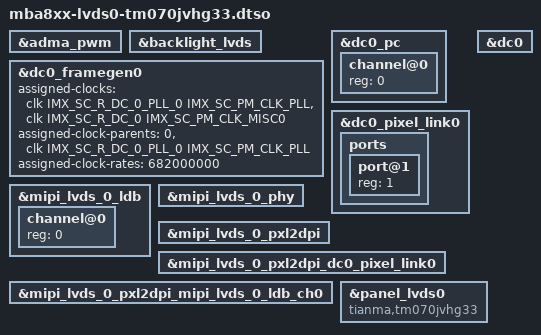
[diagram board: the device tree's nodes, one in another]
// SPDX-License-Identifier: (GPL-2.0-or-later OR MIT)
/*
 * Copyright (c) 2021-2026 TQ-Systems GmbH <linux@ew.tq-group.com>,
 * D-82229 Seefeld, Germany.
 * Author: Alexander Stein
 */

/dts-v1/;
/plugin/;

#include <dt-bindings/firmware/imx/rsrc.h>

&adma_pwm {
	status = "okay";
};

&backlight_lvds {
	status = "okay";
};

&dc0_framegen0 {
	assigned-clocks = <&clk IMX_SC_R_DC_0_PLL_0 IMX_SC_PM_CLK_PLL>,
			  <&clk IMX_SC_R_DC_0 IMX_SC_PM_CLK_MISC0>;
	assigned-clock-parents = <0>,
				 <&clk IMX_SC_R_DC_0_PLL_0 IMX_SC_PM_CLK_PLL>;
	assigned-clock-rates = <682000000>;
};

&dc0_pc {
	#address-cells = <1>;
	#size-cells = <0>;
	status = "okay";

	channel@0 {
		reg = <0>;
		status = "okay";
	};
};

&dc0_pixel_link0 {
	status = "okay";

	ports {
		#address-cells = <1>;
		#size-cells = <0>;

		port@1 {
			reg = <1>;
			status = "okay";
		};
	};
};

&dc0 {
	status = "okay";
};

&mipi_lvds_0_ldb {
	#address-cells = <1>;
	#size-cells = <0>;
	status = "okay";

	channel@0 {
		reg = <0>;
		status = "okay";
	};
};

&mipi_lvds_0_phy {
	status = "okay";
};

&mipi_lvds_0_pxl2dpi {
	status = "okay";
};

&mipi_lvds_0_pxl2dpi_dc0_pixel_link0 {
	status = "okay";
};

&mipi_lvds_0_pxl2dpi_mipi_lvds_0_ldb_ch0 {
	status = "okay";
};

&panel_lvds0 {
	compatible = "tianma,tm070jvhg33";
	status = "okay";
};
